# nrf54h20_enga_secure register map
Vendor: Nordic Semiconductor; Series: nRF54h; File version: 1
CPU: CM33 r0p4, little endian, MPU, no FPU, 3 interrupt priority bits, 480 interrupts, 4 SAU regions
Registers are 32-bit, read-write, reset 0x0 unless marked. A register's access mark holds for its fields unless they carry their own. Offsets are from the block's base; [hi:lo] are bit positions; lines under a group give offsets from that group; {n}, {i} and the like mark numbered series; 'fields as' and 'values as' point back to an identical list.

## ICACHEDATA_S — CACHEDATA 0
Base 0x11F00000
Same registers: DCACHEDATA_S 0x31F00000
{0x0+0x40*i} SET[{i}] (i=0..255) group — Unspecified
  {0x0+0x20*j} WAY[{j}] (j=0..1) group — Unspecified
    {0x0+8k} DU[{k}] (k=0..3) group — Unspecified
      {0x0+4l} DATA[{l}] (l=0..1) — Description collection: Cache data bits for DATA[q] in DU[p] (DataUnit) of SET[n], WAY[o].
        [31:0] Data ro

## ICACHEINFO_S — CACHEINFO 0
Base 0x11F10000
Same registers: DCACHEINFO_S 0x31F10000
{0x0+8i} SET[{i}] (i=0..255) group — Unspecified
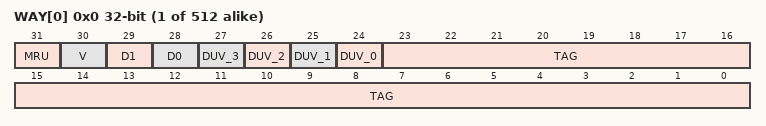
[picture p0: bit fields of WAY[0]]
  {0x0+4j} WAY[{j}] (j=0..1) — Description collection: Cache information for SET[n], WAY[o].
    [31] MRU ro — Most recently used way.
      0=Way0 was most recently used; 1=Way1 was most recently used
    [30] V ro — Line valid bit.
      0=Invalid cache line; 1=Valid cache line
    [29] D1 ro — Dirty data unit 1.
      0=Clean data unit; 1=Dirty data unit
    [28] D0 ro — Dirty data unit 0.
      0=Clean data unit; 1=Dirty data unit
    [n+24] DUV_{n} ro (n=0..3) — Data unit valid info.
      0=Invalid data unit; 1=Valid data unit
    [23:0] TAG ro — Cache tag.

## GLOBAL_STMDATA_NS — System Trace Macrocell data buffer 0
Base 0xA0000000
Same registers: GLOBAL_STMDATA_S 0xA0000000 (alternate view of GLOBAL_STMDATA_NS)
{0x0+0x2000000*i} DOMAIN[{i}] (i=0..15) group — Unspecified
  {0x0+j} NSDATA[{j}] (j=0..16777215) 8-bit — Description collection: NonSecure STM output data buffer for domain n. Writes to this region generates trace packets with id n+96.
  {0x1000000+j} SDATA[{j}] (j=0..16777215) 8-bit — Description collection: Secure STM output data buffer for domain n. Writes to this region generates trace packets with id n+32.
{0x0+0x1000000*i} BUFFER[{i}] (i=0..15) group (alternate view of DOMAIN[{i}]) — Raw buffer access to STM array. Use when DOMAIN array does not apply.
  {0x0+j} DATA[{j}] (j=0..16777215) 8-bit — Description collection: STM output data buffer n. Writes to this region generates trace packets.

## GLOBAL_TDDCONF_NS — TDDCONF 0
Base 0xBF001000
Same registers: GLOBAL_TDDCONF_S 0xBF001000 (alternate view of GLOBAL_TDDCONF_NS)
0x400 SYSPWRUPREQ — System power-up request
  [0] ACTIVE — Activate power-up request
    0=NotActive (Power-up request not active); 1=Active (Power-up request active)
0x404 DBGPWRUPREQ — Debug power-up request
  fields as SYSPWRUPREQ
0x408 TRACEPORTSPEED — Trace port trace clock speed
  [1:0] SPEED — Trace clock speed
    0=Speed25MHz; 1=Speed12500KHz (Speed 12.5MHz); 2=Speed6250KHz (Speed 6.25MHz); 3=Speed3125KHz (Speed 3.125MHz)
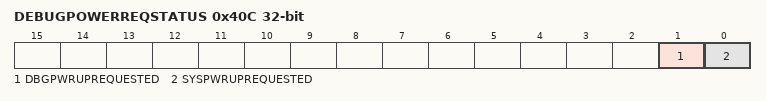
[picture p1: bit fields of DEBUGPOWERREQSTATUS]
0x40C DEBUGPOWERREQSTATUS ro — Combined effective system status of both SWJ-DP and TDDCONF registers originated power requests
  [1] DBGPWRUPREQUESTED — Debug domain powerup request status
    0=NoPowerReq (Power not requested); 1=Power requested
  [0] SYSPWRUPREQUESTED — System powerup request status
    0=NoPowerReq (Power not requested); 1=Power requested

## PCGCM200_S — PCGC Master 0
Base 0xBF006000
Same registers: PCGCM000_S 0x5100B000, PCGCM001_S 0x5100F000, PCGCM010_S 0x5101B000, PCGCM011_S 0x5101F000
{0xE0+4i} SETPWRCONTHRESHOLDBASE[{i}] (i=0..2) — Description collection: Set power consumption threshold base for power source / regulator n
  [3:0] SETPWRCONTHRESHOLDBASE
{0x100+4i} SETPOWERCONSUMPTIONBASE[{i}] (i=0..1) — Description collection: Set power consumption base for power/clock pair n
  [3:0] POWERREQUIREMENT
0xC00 UNLOCKBACKDOORS
  [15:0] UNLOCKBACKDOORS — Write: 0x00009375 to lock/unlock backdoors Read: 0x00000001 if backdoors is enabled Read: 0x00000000 if backdoors is disabled
0xC04 ENABLEPOWERREGFORCE
  [2:0] ENABLEPOWERREGFORCE
0xC08 POWERREGFORCE — Force reg
  [2:0] POWERREGFORCEREG
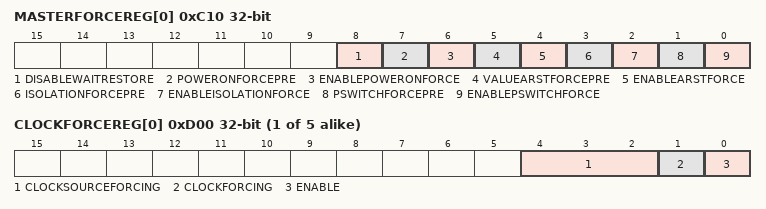
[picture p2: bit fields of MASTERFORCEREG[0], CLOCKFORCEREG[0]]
{0xC10+4i} MASTERFORCEREG[{i}] (i=0..0) — Description collection: Force reg
  [8] DISABLEWAITRESTORE — Turn off waiting for arst deactivation before retention restore
    1=Disable (Turn off waiting for arst deactivation before retention restore); 0=Enable (Wait for arst deactivation before retention restore)
  [7] POWERONFORCEPRE
  [6] ENABLEPOWERONFORCE
  [5] VALUEARSTFORCEPRE
  [4] ENABLEARSTFORCE
  [3] ISOLATIONFORCEPRE
  [2] ENABLEISOLATIONFORCE
  [1] PSWITCHFORCEPRE
  [0] ENABLEPSWITCHFORCE
{0xD00+4i} CLOCKFORCEREG[{i}] (i=0..4) — Description collection: Force clock n
  [4:2] CLOCKSOURCEFORCING
  [1] CLOCKFORCING
  [0] ENABLE — Enable clock forcing
